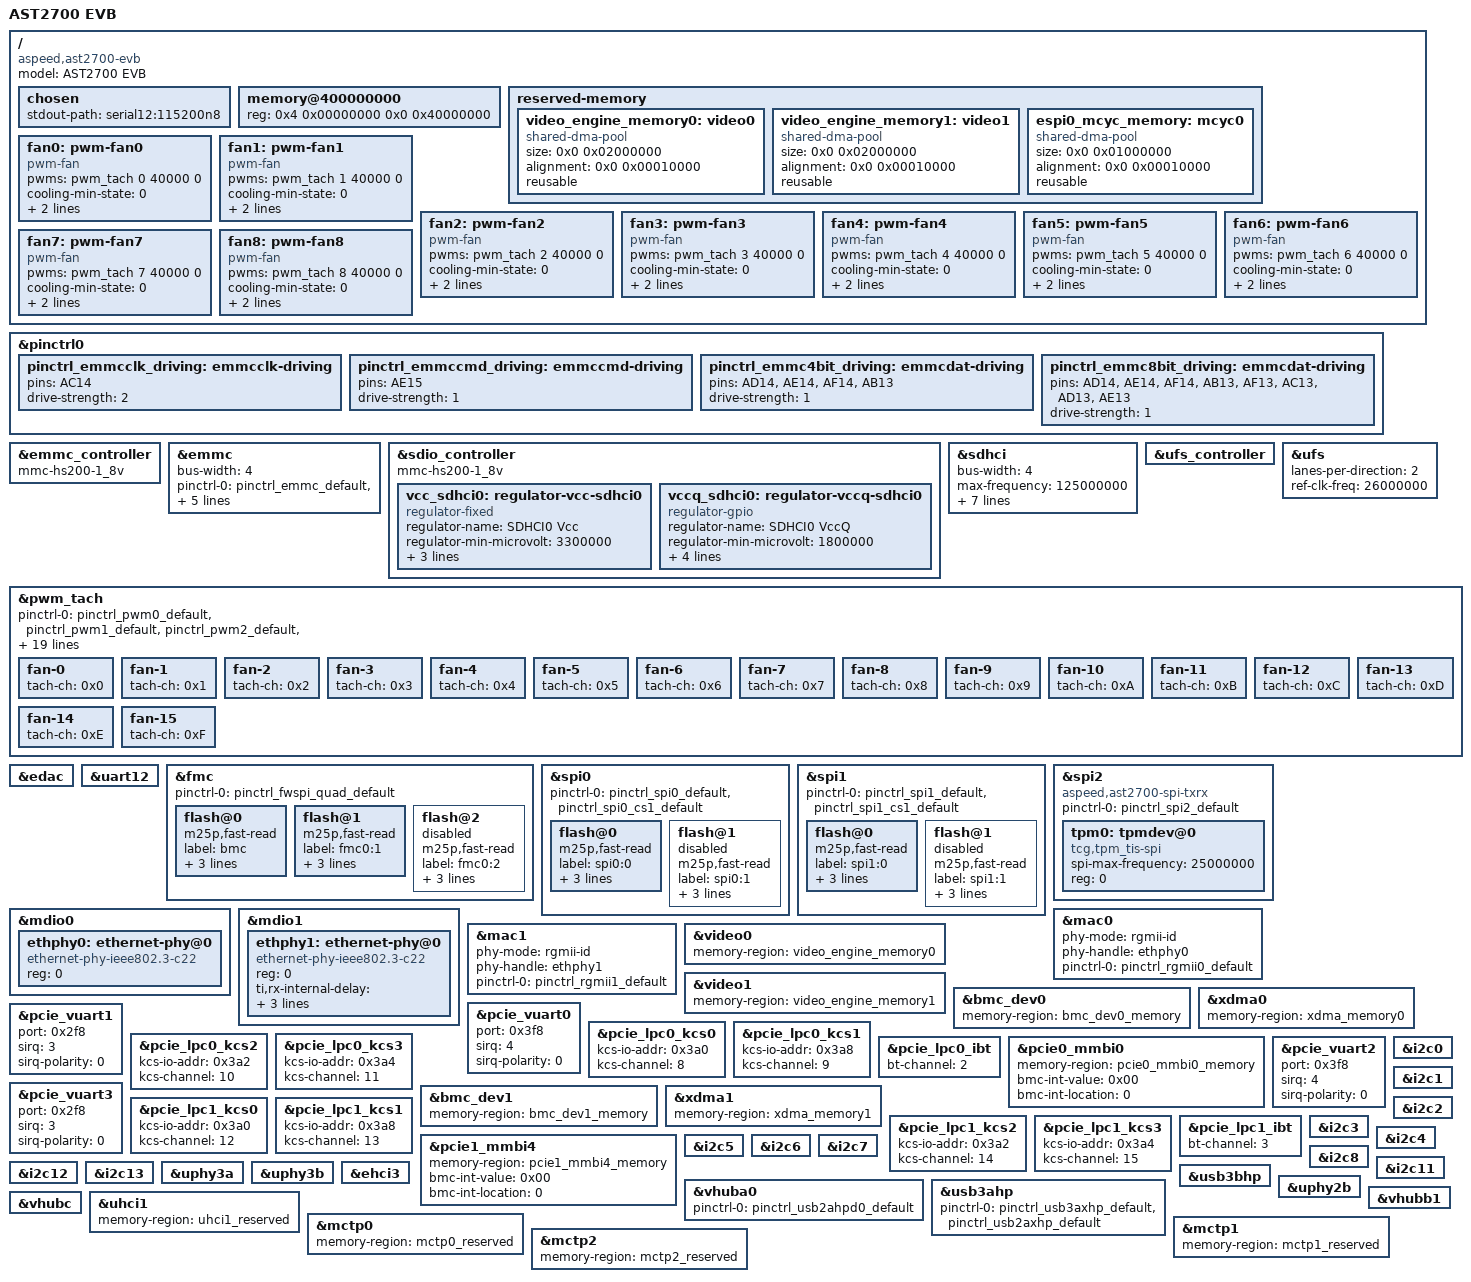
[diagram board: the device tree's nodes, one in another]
// SPDX-License-Identifier: GPL-2.0-or-later

/dts-v1/;
#include "aspeed-g7.dtsi"
#include <dt-bindings/gpio/aspeed-gpio.h>
#include <dt-bindings/net/ti-dp83867.h>

#define DUAL_NODE 0	// 1: DUAL_NODE, 0: SINGLE_NODE
#define PCIE0_EP 1	// 1: EP, 0: RC
#define PCIE1_EP 1	// 1: EP, 0: RC

/ {
	model = "AST2700 EVB";
	compatible = "aspeed,ast2700-evb", "aspeed,ast2700";

	chosen {
		stdout-path = "serial12:115200n8";
	};

	memory@400000000 {
		device_type = "memory";
		reg = <0x4 0x00000000 0x0 0x40000000>;
	};

	reserved-memory {
		#address-cells = <2>;
		#size-cells = <2>;
		ranges;

		#include "ast2700-reserved-mem.dtsi"

		video_engine_memory0: video0 {
			size = <0x0 0x02000000>;
			alignment = <0x0 0x00010000>;
			compatible = "shared-dma-pool";
			reusable;
		};

		video_engine_memory1: video1 {
			size = <0x0 0x02000000>;
			alignment = <0x0 0x00010000>;
			compatible = "shared-dma-pool";
			reusable;
		};

#if 0
		gfx_memory: framebuffer {
			size = <0x0 0x01000000>;
			alignment = <0x0 0x01000000>;
			compatible = "shared-dma-pool";
			reusable;
		};
#endif

		espi0_mcyc_memory: mcyc0 {
			size = <0x0 0x01000000>;
			alignment = <0x0 0x00010000>;
			compatible = "shared-dma-pool";
			reusable;
		};
	};

	reserved-memory {
		#address-cells = <2>;
		#size-cells = <2>;
		ranges;

		#include "ast2700-reserved-mem.dtsi"

		video_engine_memory0: video0 {
			size = <0x0 0x02000000>;
			alignment = <0x0 0x00010000>;
			compatible = "shared-dma-pool";
			reusable;
		};

		video_engine_memory1: video1 {
			size = <0x0 0x02000000>;
			alignment = <0x0 0x00010000>;
			compatible = "shared-dma-pool";
			reusable;
		};

#if 0
		gfx_memory: framebuffer {
			size = <0x0 0x01000000>;
			alignment = <0x0 0x01000000>;
			compatible = "shared-dma-pool";
			reusable;
		};
#endif

		espi0_mcyc_memory: mcyc0 {
			size = <0x0 0x01000000>;
			alignment = <0x0 0x00010000>;
			compatible = "shared-dma-pool";
			reusable;
		};
	};

	fan0: pwm-fan0 {
		compatible = "pwm-fan";
		pwms = <&pwm_tach 0 40000 0>;   /* Target freq:25 kHz */
		cooling-min-state = <0>;
		cooling-max-state = <3>;
		#cooling-cells = <2>;
		cooling-levels = <0 15 128 255>;
	};

	fan1: pwm-fan1 {
		compatible = "pwm-fan";
		pwms = <&pwm_tach 1 40000 0>;   /* Target freq:25 kHz */
		cooling-min-state = <0>;
		cooling-max-state = <3>;
		#cooling-cells = <2>;
		cooling-levels = <0 15 128 255>;
	};

	fan2: pwm-fan2 {
		compatible = "pwm-fan";
		pwms = <&pwm_tach 2 40000 0>;	/* Target freq:25 kHz */
		cooling-min-state = <0>;
		cooling-max-state = <3>;
		#cooling-cells = <2>;
		cooling-levels = <0 15 128 255>;
	};

	fan3: pwm-fan3 {
		compatible = "pwm-fan";
		pwms = <&pwm_tach 3 40000 0>;	/* Target freq:25 kHz */
		cooling-min-state = <0>;
		cooling-max-state = <3>;
		#cooling-cells = <2>;
		cooling-levels = <0 15 128 255>;
	};

	fan4: pwm-fan4 {
		compatible = "pwm-fan";
		pwms = <&pwm_tach 4 40000 0>;	/* Target freq:25 kHz */
		cooling-min-state = <0>;
		cooling-max-state = <3>;
		#cooling-cells = <2>;
		cooling-levels = <0 15 128 255>;
	};

	fan5: pwm-fan5 {
		compatible = "pwm-fan";
		pwms = <&pwm_tach 5 40000 0>;	/* Target freq:25 kHz */
		cooling-min-state = <0>;
		cooling-max-state = <3>;
		#cooling-cells = <2>;
		cooling-levels = <0 15 128 255>;
	};

	fan6: pwm-fan6 {
		compatible = "pwm-fan";
		pwms = <&pwm_tach 6 40000 0>;	/* Target freq:25 kHz */
		cooling-min-state = <0>;
		cooling-max-state = <3>;
		#cooling-cells = <2>;
		cooling-levels = <0 15 128 255>;
	};

	fan7: pwm-fan7 {
		compatible = "pwm-fan";
		pwms = <&pwm_tach 7 40000 0>;	/* Target freq:25 kHz */
		cooling-min-state = <0>;
		cooling-max-state = <3>;
		#cooling-cells = <2>;
		cooling-levels = <0 15 128 255>;
	};

	fan8: pwm-fan8 {
		compatible = "pwm-fan";
		pwms = <&pwm_tach 8 40000 0>;	/* Target freq:25 kHz */
		cooling-min-state = <0>;
		cooling-max-state = <3>;
		#cooling-cells = <2>;
		cooling-levels = <0 15 128 255>;
	};
};

&pinctrl0 {
	pinctrl_emmcclk_driving: emmcclk-driving {
		pins = "AC14";
		drive-strength = <2>;
	};

	pinctrl_emmccmd_driving: emmccmd-driving {
		pins = "AE15";
		drive-strength = <1>;
	};
	pinctrl_emmc4bit_driving: emmcdat-driving {
		pins = "AD14", "AE14", "AF14", "AB13";
		drive-strength = <1>;
	};

	pinctrl_emmc8bit_driving: emmcdat-driving {
		pins = "AD14", "AE14", "AF14", "AB13", "AF13", "AC13", "AD13", "AE13";
		drive-strength = <1>;
	};
};

&emmc_controller {
	status = "okay";
	mmc-hs200-1_8v;
};

&emmc {
	status = "okay";
#if 1
	bus-width = <4>;
	pinctrl-names = "default";
	pinctrl-0 = <&pinctrl_emmc_default
		     &pinctrl_emmcclk_driving
		     &pinctrl_emmccmd_driving
		     &pinctrl_emmc4bit_driving>;
#else
	bus-width = <8>;
	pinctrl-names = "default";
	pinctrl-0 = <&pinctrl_emmc_default
		     &pinctrl_emmcg8_default
		     &pinctrl_emmcclk_driving
		     &pinctrl_emmccmd_driving
		     &pinctrl_emmc8bit_driving>;
#endif

	non-removable;
	max-frequency = <200000000>;
};

&sdio_controller {
	status = "okay";
	mmc-hs200-1_8v;

	vcc_sdhci0: regulator-vcc-sdhci0 {
		compatible = "regulator-fixed";
		regulator-name = "SDHCI0 Vcc";
		regulator-min-microvolt = <3300000>;
		regulator-max-microvolt = <3300000>;
		gpios = <&gpio1 ASPEED_GPIO(G, 6) GPIO_ACTIVE_HIGH>;
		enable-active-high;
	};

	vccq_sdhci0: regulator-vccq-sdhci0 {
		compatible = "regulator-gpio";
		regulator-name = "SDHCI0 VccQ";
		regulator-min-microvolt = <1800000>;
		regulator-max-microvolt = <3300000>;
		gpios = <&gpio1 ASPEED_GPIO(G, 7) GPIO_ACTIVE_HIGH>;
		gpios-states = <1>;
		states = <3300000 1>,
			 <1800000 0>;
	};
};

&sdhci {
	status = "okay";
	bus-width = <4>;
	max-frequency = <125000000>;
	/* DDR50 bits in CAPA2 are not supported */
	sdhci-caps-mask = <0x6 0x0>;
	sdhci-drive-type = /bits/ 8 <3>;
	post-power-on-delay-ms = <50>;
	pinctrl-names = "default";
	pinctrl-0 = <&pinctrl_sd_default>;
	vmmc-supply = <&vcc_sdhci0>;
	vqmmc-supply = <&vccq_sdhci0>;
	sd-uhs-sdr104; /* enable sdr104 to execute tuning */
};

&ufs_controller {
	status = "okay";
};

&ufs {
	status = "okay";
	lanes-per-direction = <2>;
	ref-clk-freq = <26000000>;
};

&pwm_tach {
	status = "okay";
	pinctrl-names = "default";
	pinctrl-0 = <&pinctrl_pwm0_default &pinctrl_pwm1_default
		     &pinctrl_pwm2_default &pinctrl_pwm3_default
		     &pinctrl_pwm4_default &pinctrl_pwm5_default
		     &pinctrl_pwm6_default &pinctrl_pwm7_default
		     &pinctrl_pwm8_default
		     &pinctrl_tach0_default &pinctrl_tach1_default
		     &pinctrl_tach2_default &pinctrl_tach3_default
		     &pinctrl_tach4_default &pinctrl_tach5_default
		     &pinctrl_tach6_default &pinctrl_tach7_default
		     &pinctrl_tach8_default &pinctrl_tach9_default
		     &pinctrl_tach10_default &pinctrl_tach11_default
		     &pinctrl_tach12_default &pinctrl_tach13_default
		     &pinctrl_tach14_default &pinctrl_tach15_default>;
	fan-0 {
		tach-ch = /bits/ 8 <0x0>;
	};
	fan-1 {
		tach-ch = /bits/ 8 <0x1>;
	};
	fan-2 {
		tach-ch = /bits/ 8 <0x2>;
	};
	fan-3 {
		tach-ch = /bits/ 8 <0x3>;
	};
	fan-4 {
		tach-ch = /bits/ 8 <0x4>;
	};
	fan-5 {
		tach-ch = /bits/ 8 <0x5>;
	};
	fan-6 {
		tach-ch = /bits/ 8 <0x6>;
	};
	fan-7 {
		tach-ch = /bits/ 8 <0x7>;
	};
	fan-8 {
		tach-ch = /bits/ 8 <0x8>;
	};
	fan-9 {
		tach-ch = /bits/ 8 <0x9>;
	};
	fan-10 {
		tach-ch = /bits/ 8 <0xA>;
	};
	fan-11 {
		tach-ch = /bits/ 8 <0xB>;
	};
	fan-12 {
		tach-ch = /bits/ 8 <0xC>;
	};
	fan-13 {
		tach-ch = /bits/ 8 <0xD>;
	};
	fan-14 {
		tach-ch = /bits/ 8 <0xE>;
	};
	fan-15 {
		tach-ch = /bits/ 8 <0xF>;
	};
};

&edac {
	status = "okay";
};

&uart12 {
	status = "okay";
};

&fmc {
	status = "okay";
	pinctrl-0 = <&pinctrl_fwspi_quad_default>;
	pinctrl-names = "default";

	flash@0 {
		status = "okay";
		m25p,fast-read;
		label = "bmc";
		spi-max-frequency = <50000000>;
		spi-tx-bus-width = <4>;
		spi-rx-bus-width = <4>;
#include "aspeed-evb-flash-layout-128.dtsi"
	};

	flash@1 {
		status = "okay";
		m25p,fast-read;
		label = "fmc0:1";
		spi-max-frequency = <50000000>;
		spi-tx-bus-width = <4>;
		spi-rx-bus-width = <4>;
	};

	flash@2 {
		status = "disabled";
		m25p,fast-read;
		label = "fmc0:2";
		spi-max-frequency = <50000000>;
		spi-tx-bus-width = <4>;
		spi-rx-bus-width = <4>;
	};
};

&spi0 {
	status = "okay";
	pinctrl-0 = <&pinctrl_spi0_default &pinctrl_spi0_cs1_default>;
	pinctrl-names = "default";

	flash@0 {
		status = "okay";
		m25p,fast-read;
		label = "spi0:0";
		spi-max-frequency = <50000000>;
		spi-tx-bus-width = <2>;
		spi-rx-bus-width = <2>;
	};

	flash@1 {
		status = "disabled";
		m25p,fast-read;
		label = "spi0:1";
		spi-max-frequency = <50000000>;
		spi-tx-bus-width = <2>;
		spi-rx-bus-width = <2>;
	};
};

&spi1 {
	status = "okay";
	pinctrl-0 = <&pinctrl_spi1_default &pinctrl_spi1_cs1_default>;
	pinctrl-names = "default";

	flash@0 {
		status = "okay";
		m25p,fast-read;
		label = "spi1:0";
		spi-max-frequency = <50000000>;
		spi-tx-bus-width = <2>;
		spi-rx-bus-width = <2>;
	};

	flash@1 {
		status = "disabled";
		m25p,fast-read;
		label = "spi1:1";
		spi-max-frequency = <50000000>;
		spi-tx-bus-width = <2>;
		spi-rx-bus-width = <2>;
	};
};

#if 1
&spi2 {
	compatible = "aspeed,ast2700-spi-txrx";
	pinctrl-0 = <&pinctrl_spi2_default>;
	pinctrl-names = "default";
	status = "okay";

	tpm0: tpmdev@0 {
		compatible = "tcg,tpm_tis-spi";
		spi-max-frequency = <25000000>;
		reg = <0>;
		status = "okay";
	};
};
#else
&spi2 {
	compatible = "aspeed,ast2700-spi";
	pinctrl-0 = <&pinctrl_spi2_default &pinctrl_spi2_cs1_default>;
	pinctrl-names = "default";
	status = "okay";

	flash@0 {
		status = "okay";
		reg = < 0 >;
		compatible = "jedec,spi-nor";
		m25p,fast-read;
		label = "spi2:0";
		spi-max-frequency = <50000000>;
		spi-tx-bus-width = <2>;
		spi-rx-bus-width = <2>;
	};

	flash@1 {
		status = "okay";
		reg = < 1 >;
		compatible = "jedec,spi-nor";
		m25p,fast-read;
		label = "spi2:1";
		spi-max-frequency = <50000000>;
		spi-tx-bus-width = <2>;
		spi-rx-bus-width = <2>;
	};
};
#endif

&mdio0 {
	status = "okay";
	#address-cells = <1>;
	#size-cells = <0>;

	ethphy0: ethernet-phy@0 {
		compatible = "ethernet-phy-ieee802.3-c22";
		reg = <0>;
	};
};

&mdio1 {
	status = "okay";
	#address-cells = <1>;
	#size-cells = <0>;

	ethphy1: ethernet-phy@0 {
		compatible = "ethernet-phy-ieee802.3-c22";
		reg = <0>;
		/* For DDR5 board */
		ti,rx-internal-delay = <DP83867_RGMIIDCTL_2_00_NS>;
		ti,tx-internal-delay = <DP83867_RGMIIDCTL_2_00_NS>;
	};
};

&mac0 {
	status = "okay";

	phy-mode = "rgmii-id";
	phy-handle = <&ethphy0>;

	pinctrl-names = "default";
	pinctrl-0 = <&pinctrl_rgmii0_default>;
};

&mac1 {
	status = "okay";

	phy-mode = "rgmii-id";
	phy-handle = <&ethphy1>;

	pinctrl-names = "default";
	pinctrl-0 = <&pinctrl_rgmii1_default>;
};

#if 0			// Default to disable RC & SGMII
#define PCIE2_RC 1	// 1: RC, 0: SGMII
#if PCIE2_RC
&pcie2 {
	status = "okay";
};
#else
&mdio2 {
	status = "okay";
	#address-cells = <1>;
	#size-cells = <0>;

	ethphy2: ethernet-phy@0 {
		compatible = "ethernet-phy-ieee802.3-c22";
		reg = <0>;
	};
};

&sgmii {
	status = "okay";
};

&mac2 {
	status = "okay";

	phy-mode = "sgmii";
	phy-handle = <&ethphy2>;
};
#endif
#endif

&video0 {
	status = "okay";
	memory-region = <&video_engine_memory0>;
};

&video1 {
	status = "okay";
	memory-region = <&video_engine_memory1>;
};

#if PCIE0_EP
&bmc_dev0 {
	status = "okay";
	memory-region = <&bmc_dev0_memory>;
};

&xdma0 {
	status = "okay";
	memory-region = <&xdma_memory0>;
};

&pcie_vuart0 {
	port = <0x3f8>;
	sirq = <4>;
	sirq-polarity = <0>;

	status = "okay";
};

&pcie_vuart1 {
	port = <0x2f8>;
	sirq = <3>;
	sirq-polarity = <0>;

	status = "okay";
};

&pcie_lpc0_kcs0 {
	status = "okay";
	kcs-io-addr = <0x3a0>;
	kcs-channel = <8>;
};

&pcie_lpc0_kcs1 {
	status = "okay";
	kcs-io-addr = <0x3a8>;
	kcs-channel = <9>;
};

&pcie_lpc0_kcs2 {
	status = "okay";
	kcs-io-addr = <0x3a2>;
	kcs-channel = <10>;
};

&pcie_lpc0_kcs3 {
	status = "okay";
	kcs-io-addr = <0x3a4>;
	kcs-channel = <11>;
};

&pcie_lpc0_ibt {
	status = "okay";
	bt-channel = <2>;
};

&pcie0_mmbi0 {
	status = "okay";
	memory-region = <&pcie0_mmbi0_memory>;

	bmc-int-value = /bits/ 8 <0x00>;
	bmc-int-location = <0>;
};
#else /* !PCIE0_EP */
&pcie0 {
	status = "okay";
};
#endif /* PCIE0_EP */

#if PCIE1_EP
&bmc_dev1 {
	status = "okay";
	memory-region = <&bmc_dev1_memory>;
};

&xdma1 {
	status = "okay";
	memory-region = <&xdma_memory1>;
};

&pcie_vuart2 {
	port = <0x3f8>;
	sirq = <4>;
	sirq-polarity = <0>;

	status = "okay";
};

&pcie_vuart3 {
	port = <0x2f8>;
	sirq = <3>;
	sirq-polarity = <0>;

	status = "okay";
};

&pcie_lpc1_kcs0 {
	status = "okay";
	kcs-io-addr = <0x3a0>;
	kcs-channel = <12>;
};

&pcie_lpc1_kcs1 {
	status = "okay";
	kcs-io-addr = <0x3a8>;
	kcs-channel = <13>;
};

&pcie_lpc1_kcs2 {
	status = "okay";
	kcs-io-addr = <0x3a2>;
	kcs-channel = <14>;
};

&pcie_lpc1_kcs3 {
	status = "okay";
	kcs-io-addr = <0x3a4>;
	kcs-channel = <15>;
};

&pcie_lpc1_ibt {
	status = "okay";
	bt-channel = <3>;
};

&pcie1_mmbi4 {
	status = "okay";
	memory-region = <&pcie1_mmbi4_memory>;

	bmc-int-value = /bits/ 8 <0x00>;
	bmc-int-location = <0>;
};
#else /* !PCIE1_EP */
&pcie1 {
	status = "okay";
};
#endif /* PCIE1_EP */

#if 1
&i2c0 {
	status = "okay";
};

&i2c1 {
	status = "okay";
};

&i2c2 {
	status = "okay";
};

&i2c3 {
	status = "okay";
};

&i2c4 {
	status = "okay";
};

&i2c5 {
	status = "okay";
};

&i2c6 {
	status = "okay";
};

&i2c7 {
	status = "okay";
};

&i2c8 {
	status = "okay";
};

&i2c11 {
	status = "okay";
};

&i2c12 {
	status = "okay";
};

&i2c13 {
	status = "okay";
};
#endif

#if 0
&ehci0 {
	status = "okay";
};

&ehci1 {
	status = "okay";
};

&uhci0 {
	status = "okay";
	memory-region = <&uhci0_reserved>;
};
#endif

#if 1
&uphy3a {
	status = "okay";
};

&uphy3b {
	status = "okay";
};
#endif

#if 0
&xhci0 {
	status = "okay";
};

&xhci1 {
	status = "okay";
};
#endif

&vhuba0 {
	status = "okay";
	pinctrl-0 = <&pinctrl_usb2ahpd0_default>;
};

&usb3ahp {
	status = "okay";
	pinctrl-0 = <&pinctrl_usb3axhp_default &pinctrl_usb2axhp_default>;
};

&usb3bhp {
	status = "okay";
};

&uphy2b {
	status = "okay";
};

&vhubb1 {
	status = "okay";
};

&vhubc {
	status = "okay";
#if 0
	pinctrl-0 = <&pinctrl_usb2cud_default>;
	aspeed,uart-ports = <12>;
#endif
};

&ehci3 {
	status = "okay";
};

&uhci1 {
	status = "okay";
	memory-region = <&uhci1_reserved>;
};

&mctp0 {
	status = "okay";
	memory-region = <&mctp0_reserved>;
};

&mctp1 {
	status = "okay";
	memory-region = <&mctp1_reserved>;
};

&mctp2 {
	status = "okay";
	memory-region = <&mctp2_reserved>;
};

#if 0
&soc0 {
	mbox-ssp-0 {
		compatible = "aspeed,aspeed-mbox";
		reg = <0x4 0x31480000 0x0 0x200000>, <0x0 0x10001000 0x0 0x1000>;
		mboxes = <&mbox0 0>;
		aspeed,tx-timeout = <100>;
	};
};
#endif
